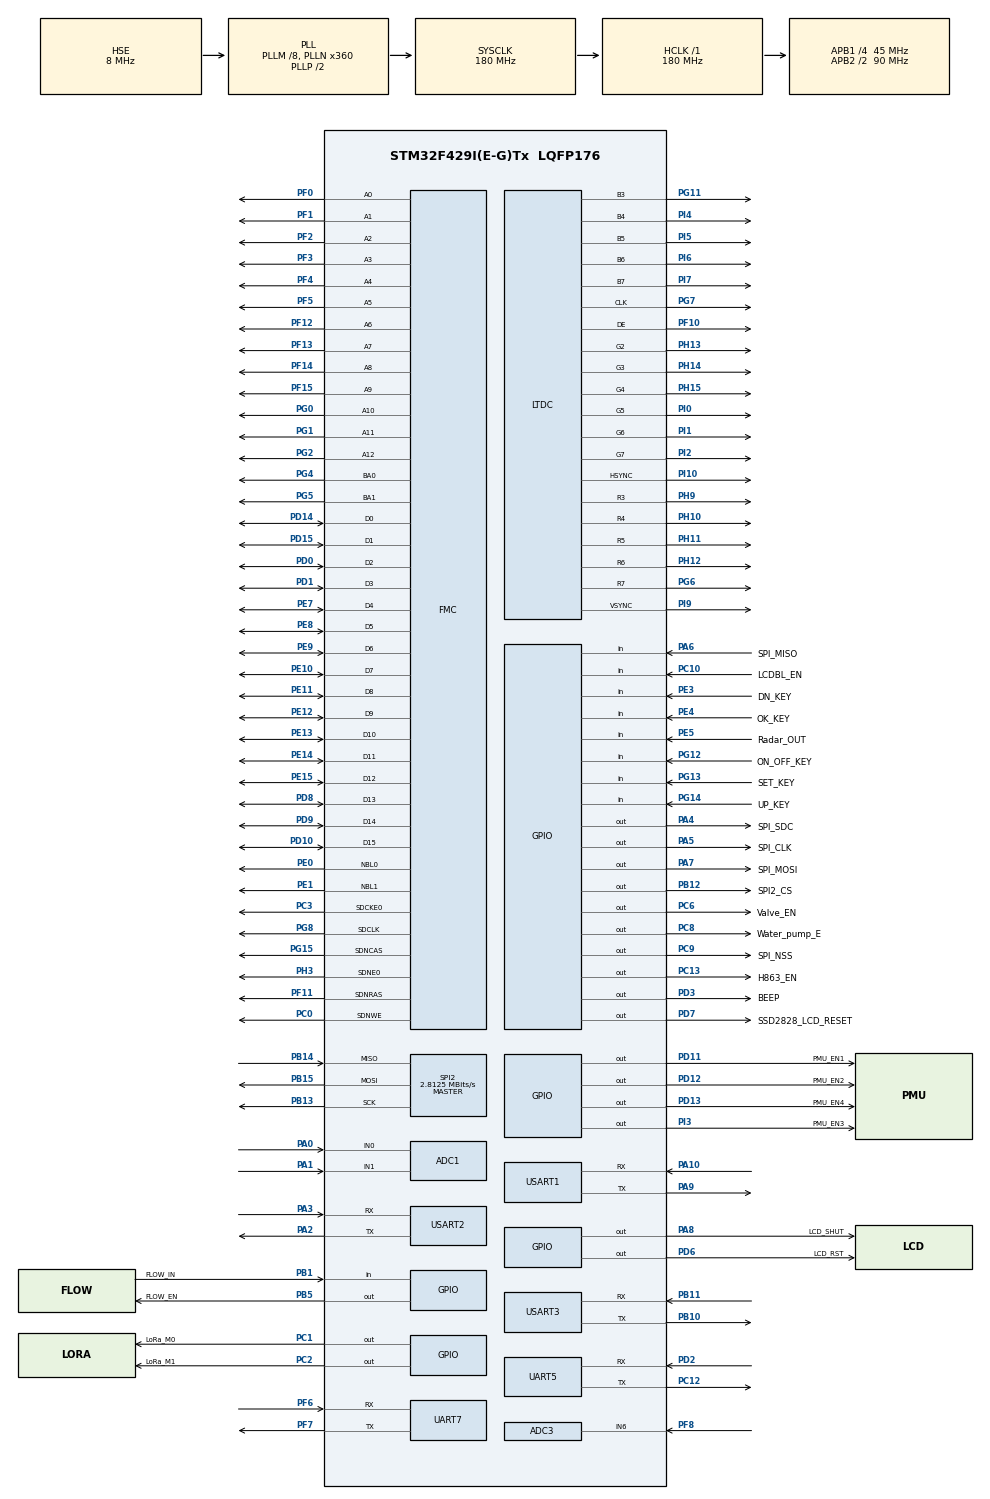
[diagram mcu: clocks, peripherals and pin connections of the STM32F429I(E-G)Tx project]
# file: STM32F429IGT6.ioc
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ADC1.Channel-1\#ChannelRegularConversion=ADC_CHANNEL_0
ADC1.Channel-2\#ChannelRegularConversion=ADC_CHANNEL_1
ADC1.ClockPrescaler=ADC_CLOCK_SYNC_PCLK_DIV4
ADC1.NbrOfConversion=2
ADC1.NbrOfConversionFlag=1
ADC1.Rank-1\#ChannelRegularConversion=1
ADC1.Rank-2\#ChannelRegularConversion=2
ADC1.SamplingTime-1\#ChannelRegularConversion=ADC_SAMPLETIME_144CYCLES
ADC1.SamplingTime-2\#ChannelRegularConversion=ADC_SAMPLETIME_144CYCLES
ADC1.ScanConvMode=ENABLE
ADC1.master=1
ADC3.Channel-0\#ChannelRegularConversion=ADC_CHANNEL_6
ADC3.ClockPrescaler=ADC_CLOCK_SYNC_PCLK_DIV4
ADC3.NbrOfConversionFlag=1
ADC3.Rank-0\#ChannelRegularConversion=1
ADC3.SamplingTime-0\#ChannelRegularConversion=ADC_SAMPLETIME_144CYCLES
FMC.CASLatency1=FMC_SDRAM_CAS_LATENCY_3
FMC.ColumnBitsNumber1=FMC_SDRAM_COLUMN_BITS_NUM_9
FMC.ExitSelfRefreshDelay1=8
FMC.LoadToActiveDelay1=2
FMC.RCDDelay1=3
FMC.RPDelay1=3
FMC.RPDelay2=3
FMC.ReadBurst1=FMC_SDRAM_RBURST_ENABLE
FMC.ReadBurst2=FMC_SDRAM_RBURST_ENABLE
FMC.ReadPipeDelay1=FMC_SDRAM_RPIPE_DELAY_1
FMC.ReadPipeDelay2=FMC_SDRAM_RPIPE_DELAY_1
FMC.RowCycleDelay1=8
FMC.RowCycleDelay2=8
FMC.SDClockPeriod1=FMC_SDRAM_CLOCK_PERIOD_2
FMC.SDClockPeriod2=FMC_SDRAM_CLOCK_PERIOD_2
FMC.SelfRefreshTime1=5
FMC.WriteRecoveryTime1=3
LTDC.ActiveH=960
LTDC.ActiveW=400
LTDC.Alpha_L0=255
LTDC.DEPolarity=LTDC_DEPOLARITY_AH
LTDC.FBStartAdress_L0=0xC0000000
LTDC.HBP=20
LTDC.HFP=20
LTDC.HSync=10
LTDC.ImageHeight_L0=960
LTDC.ImageWidth_L0=400
LTDC.Layers=0
LTDC.PixelFormat_L0=LTDC_PIXEL_FORMAT_RGB565
LTDC.VBP=24
LTDC.VFP=12
LTDC.VSync=8
LTDC.WindowX1_L0=400
LTDC.WindowY1_L0=960
Mcu.Family=STM32F4
Mcu.Name=STM32F429I(E-G)Tx
Mcu.Package=LQFP176
NVIC.PriorityGroup=NVIC_PRIORITYGROUP_4
PA0/WKUP.Signal=ADCx_IN0
PA1.Signal=ADCx_IN1
PA10.Mode=Asynchronous
PA10.Signal=USART1_RX
PA13.Mode=Serial_Wire
PA13.Signal=SYS_JTMS-SWDIO
PA14.Mode=Serial_Wire
PA14.Signal=SYS_JTCK-SWCLK
PA2.Mode=Asynchronous
PA2.Signal=USART2_TX
PA3.Mode=Asynchronous
PA3.Signal=USART2_RX
PA4.GPIO_Label=SPI_SDC
PA4.PinState=GPIO_PIN_SET
PA4.Signal=GPIO_Output
PA5.GPIO_Label=SPI_CLK
PA5.Signal=GPIO_Output
PA6.GPIO_Label=SPI_MISO
PA6.Signal=GPIO_Input
PA7.GPIO_Label=SPI_MOSI
PA7.Signal=GPIO_Output
PA8.GPIO_Label=LCD_SHUT
PA8.Signal=GPIO_Output
PA9.Mode=Asynchronous
PA9.Signal=USART1_TX
PB1.GPIO_Label=FLOW_IN
PB1.Signal=GPIO_Input
PB10.Mode=Asynchronous
PB10.Signal=USART3_TX
PB11.Mode=Asynchronous
PB11.Signal=USART3_RX
PB12.GPIO_Label=SPI2_CS
PB12.PinState=GPIO_PIN_SET
PB12.Signal=GPIO_Output
PB13.Mode=Full_Duplex_Master
PB13.Signal=SPI2_SCK
PB14.Mode=Full_Duplex_Master
PB14.Signal=SPI2_MISO
PB15.Mode=Full_Duplex_Master
PB15.Signal=SPI2_MOSI
PB5.GPIO_Label=FLOW_EN
PB5.PinState=GPIO_PIN_SET
PB5.Signal=GPIO_Output
PC0.Signal=FMC_SDNWE
PC1.GPIO_Label=LoRa_M0
PC1.Signal=GPIO_Output
PC10.GPIO_Label=LCDBL_EN
PC10.Signal=GPIO_Input
PC12.Mode=Asynchronous
PC12.Signal=UART5_TX
PC13.GPIO_Label=H863_EN
PC13.Signal=GPIO_Output
PC14/OSC32_IN.Mode=LSE-External-Oscillator
PC14/OSC32_IN.Signal=RCC_OSC32_IN
PC15/OSC32_OUT.Mode=LSE-External-Oscillator
PC15/OSC32_OUT.Signal=RCC_OSC32_OUT
PC2.GPIO_Label=LoRa_M1
PC2.Signal=GPIO_Output
PC3.Mode=SdramChipSelect1_1
PC3.Signal=FMC_SDCKE0
PC6.GPIO_Label=Valve_EN
PC6.Signal=GPIO_Output
PC8.GPIO_Label=Water_pump_E
PC8.Signal=GPIO_Output
PC9.GPIO_Label=SPI_NSS
PC9.PinState=GPIO_PIN_SET
PC9.Signal=GPIO_Output
PD0.Signal=FMC_D2_DA2
PD1.Signal=FMC_D3_DA3
PD10.Signal=FMC_D15_DA15
PD11.GPIO_Label=PMU_EN1
PD11.Signal=GPIO_Output
PD12.GPIO_Label=PMU_EN2
PD12.Signal=GPIO_Output
PD13.GPIO_Label=PMU_EN4
PD13.Signal=GPIO_Output
PD14.Signal=FMC_D0_DA0
PD15.Signal=FMC_D1_DA1
PD2.Mode=Asynchronous
PD2.Signal=UART5_RX
PD3.GPIO_Label=BEEP
PD3.Signal=GPIO_Output
PD6.GPIO_Label=LCD_RST
PD6.Signal=GPIO_Output
PD7.GPIO_Label=SSD2828_LCD_RESET
PD7.Signal=GPIO_Output
PD8.Signal=FMC_D13_DA13
PD9.Signal=FMC_D14_DA14
PE0.Signal=FMC_NBL0
PE1.Signal=FMC_NBL1
PE10.Signal=FMC_D7_DA7
PE11.Signal=FMC_D8_DA8
PE12.Signal=FMC_D9_DA9
PE13.Signal=FMC_D10_DA10
PE14.Signal=FMC_D11_DA11
PE15.Signal=FMC_D12_DA12
PE3.GPIO_Label=DN_KEY
PE3.GPIO_PuPd=GPIO_PULLUP
PE3.Signal=GPIO_Input
PE4.GPIO_Label=OK_KEY
PE4.GPIO_PuPd=GPIO_PULLUP
PE4.Signal=GPIO_Input
PE5.GPIO_Label=Radar_OUT
PE5.Signal=GPIO_Input
PE7.Signal=FMC_D4_DA4
PE8.Signal=FMC_D5_DA5
PE9.Signal=FMC_D6_DA6
PF0.Signal=FMC_A0
PF1.Signal=FMC_A1
PF10.GPIO_Speed=GPIO_SPEED_FREQ_VERY_HIGH
PF10.Mode=RGB565
PF10.Signal=LTDC_DE
PF11.Signal=FMC_SDNRAS
PF12.Signal=FMC_A6
PF13.Signal=FMC_A7
PF14.Signal=FMC_A8
PF15.Signal=FMC_A9
PF2.Signal=FMC_A2
PF3.Signal=FMC_A3
PF4.Signal=FMC_A4
PF5.Signal=FMC_A5
PF6.Mode=Asynchronous
PF6.Signal=UART7_RX
PF7.Mode=Asynchronous
PF7.Signal=UART7_TX
PF8.Mode=IN6
PF8.Signal=ADC3_IN6
PG0.Signal=FMC_A10
PG1.Signal=FMC_A11
PG11.GPIO_Speed=GPIO_SPEED_FREQ_VERY_HIGH
PG11.Mode=RGB565
PG11.Signal=LTDC_B3
PG12.GPIO_Label=ON_OFF_KEY
PG12.GPIO_PuPd=GPIO_PULLUP
PG12.Signal=GPIO_Input
PG13.GPIO_Label=SET_KEY
PG13.GPIO_PuPd=GPIO_PULLUP
PG13.Signal=GPIO_Input
PG14.GPIO_Label=UP_KEY
PG14.GPIO_PuPd=GPIO_PULLUP
PG14.Signal=GPIO_Input
PG15.Signal=FMC_SDNCAS
PG2.Signal=FMC_A12
PG4.Signal=FMC_A14_BA0
PG5.Signal=FMC_A15_BA1
PG6.GPIO_Speed=GPIO_SPEED_FREQ_VERY_HIGH
PG6.Mode=RGB565
PG6.Signal=LTDC_R7
PG7.GPIO_Speed=GPIO_SPEED_FREQ_VERY_HIGH
PG7.Mode=RGB565
PG7.Signal=LTDC_CLK
PG8.Signal=FMC_SDCLK
PH0/OSC_IN.Mode=HSE-External-Oscillator
PH0/OSC_IN.Signal=RCC_OSC_IN
PH1/OSC_OUT.Mode=HSE-External-Oscillator
PH1/OSC_OUT.Signal=RCC_OSC_OUT
PH10.GPIO_Speed=GPIO_SPEED_FREQ_VERY_HIGH
PH10.Mode=RGB565
PH10.Signal=LTDC_R4
PH11.GPIO_Speed=GPIO_SPEED_FREQ_VERY_HIGH
PH11.Mode=RGB565
PH11.Signal=LTDC_R5
PH12.GPIO_Speed=GPIO_SPEED_FREQ_VERY_HIGH
PH12.Mode=RGB565
PH12.Signal=LTDC_R6
PH13.GPIO_Speed=GPIO_SPEED_FREQ_VERY_HIGH
PH13.Mode=RGB565
PH13.Signal=LTDC_G2
PH14.GPIO_Speed=GPIO_SPEED_FREQ_VERY_HIGH
PH14.Mode=RGB565
PH14.Signal=LTDC_G3
PH15.GPIO_Speed=GPIO_SPEED_FREQ_VERY_HIGH
PH15.Mode=RGB565
PH15.Signal=LTDC_G4
PH3.Mode=SdramChipSelect1_1
PH3.Signal=FMC_SDNE0
PH9.GPIO_Speed=GPIO_SPEED_FREQ_VERY_HIGH
PH9.Mode=RGB565
PH9.Signal=LTDC_R3
PI0.GPIO_Speed=GPIO_SPEED_FREQ_VERY_HIGH
PI0.Mode=RGB565
PI0.Signal=LTDC_G5
PI1.GPIO_Speed=GPIO_SPEED_FREQ_VERY_HIGH
PI1.Mode=RGB565
PI1.Signal=LTDC_G6
PI10.GPIO_Speed=GPIO_SPEED_FREQ_VERY_HIGH
PI10.Mode=RGB565
PI10.Signal=LTDC_HSYNC
PI2.GPIO_Speed=GPIO_SPEED_FREQ_VERY_HIGH
PI2.Mode=RGB565
PI2.Signal=LTDC_G7
PI3.GPIO_Label=PMU_EN3
PI3.Signal=GPIO_Output
PI4.GPIO_Speed=GPIO_SPEED_FREQ_VERY_HIGH
PI4.Mode=RGB565
PI4.Signal=LTDC_B4
PI5.GPIO_Speed=GPIO_SPEED_FREQ_VERY_HIGH
PI5.Mode=RGB565
PI5.Signal=LTDC_B5
PI6.GPIO_Speed=GPIO_SPEED_FREQ_VERY_HIGH
PI6.Mode=RGB565
PI6.Signal=LTDC_B6
PI7.GPIO_Speed=GPIO_SPEED_FREQ_VERY_HIGH
PI7.Mode=RGB565
PI7.Signal=LTDC_B7
PI9.GPIO_Speed=GPIO_SPEED_FREQ_VERY_HIGH
PI9.Mode=RGB565
PI9.Signal=LTDC_VSYNC
ProjectManager.HeapSize=0x200
ProjectManager.StackSize=0x400
ProjectManager.TargetToolchain=CMake
RCC.48MHZClocksFreq_Value=90000000
RCC.AHBFreq_Value=180000000
RCC.APB1CLKDivider=RCC_HCLK_DIV4
RCC.APB1Freq_Value=45000000
RCC.APB1TimFreq_Value=90000000
RCC.APB2CLKDivider=RCC_HCLK_DIV2
RCC.APB2Freq_Value=90000000
RCC.APB2TimFreq_Value=180000000
RCC.CortexFreq_Value=180000000
RCC.HCLKFreq_Value=180000000
RCC.HSE_VALUE=8000000
RCC.HSI_VALUE=16000000
RCC.PLLM=8
RCC.PLLN=360
RCC.PLLSAIN=271
RCC.PLLSAIR=5
RCC.PLLSourceVirtual=RCC_PLLSOURCE_HSE
RCC.RCC_RTC_Clock_Source=RCC_RTCCLKSOURCE_LSI
RCC.RCC_RTC_Clock_SourceVirtual=RCC_RTCCLKSOURCE_LSI
RCC.SYSCLKFreq_VALUE=180000000
RCC.SYSCLKSource=RCC_SYSCLKSOURCE_PLLCLK
RCC.VCOOutputFreq_Value=360000000
SH.ADCx_IN0.0=ADC1_IN0,IN0
SH.ADCx_IN1.0=ADC1_IN1,IN1
SH.FMC_A0.0=FMC_A0,13b-sda1
SH.FMC_A1.0=FMC_A1,13b-sda1
SH.FMC_A10.0=FMC_A10,13b-sda1
SH.FMC_A11.0=FMC_A11,13b-sda1
SH.FMC_A12.0=FMC_A12,13b-sda1
SH.FMC_A14_BA0.0=FMC_BA0,FourSdramBanks1
SH.FMC_A15_BA1.0=FMC_BA1,FourSdramBanks1
SH.FMC_A2.0=FMC_A2,13b-sda1
SH.FMC_A3.0=FMC_A3,13b-sda1
SH.FMC_A4.0=FMC_A4,13b-sda1
SH.FMC_A5.0=FMC_A5,13b-sda1
SH.FMC_A6.0=FMC_A6,13b-sda1
SH.FMC_A7.0=FMC_A7,13b-sda1
SH.FMC_A8.0=FMC_A8,13b-sda1
SH.FMC_A9.0=FMC_A9,13b-sda1
SH.FMC_D0_DA0.0=FMC_D0,sd-16b-d1
SH.FMC_D10_DA10.0=FMC_D10,sd-16b-d1
SH.FMC_D11_DA11.0=FMC_D11,sd-16b-d1
SH.FMC_D12_DA12.0=FMC_D12,sd-16b-d1
SH.FMC_D13_DA13.0=FMC_D13,sd-16b-d1
SH.FMC_D14_DA14.0=FMC_D14,sd-16b-d1
SH.FMC_D15_DA15.0=FMC_D15,sd-16b-d1
SH.FMC_D1_DA1.0=FMC_D1,sd-16b-d1
SH.FMC_D2_DA2.0=FMC_D2,sd-16b-d1
SH.FMC_D3_DA3.0=FMC_D3,sd-16b-d1
SH.FMC_D4_DA4.0=FMC_D4,sd-16b-d1
SH.FMC_D5_DA5.0=FMC_D5,sd-16b-d1
SH.FMC_D6_DA6.0=FMC_D6,sd-16b-d1
SH.FMC_D7_DA7.0=FMC_D7,sd-16b-d1
SH.FMC_D8_DA8.0=FMC_D8,sd-16b-d1
SH.FMC_D9_DA9.0=FMC_D9,sd-16b-d1
SH.FMC_NBL0.0=FMC_NBL0,Sd2ByteEnable1
SH.FMC_NBL1.0=FMC_NBL1,Sd2ByteEnable1
SH.FMC_SDCLK.0=FMC_SDCLK,13b-sda1
SH.FMC_SDNCAS.0=FMC_SDNCAS,13b-sda1
SH.FMC_SDNRAS.0=FMC_SDNRAS,13b-sda1
SH.FMC_SDNWE.0=FMC_SDNWE,13b-sda1
SPI2.BaudRatePrescaler=SPI_BAUDRATEPRESCALER_16
SPI2.CalculateBaudRate=2.8125 MBits/s
SPI2.Direction=SPI_DIRECTION_2LINES
SPI2.Mode=SPI_MODE_MASTER
SPI2.VirtualType=VM_MASTER
UART5.VirtualMode=Asynchronous
UART7.VirtualMode=Asynchronous
USART1.VirtualMode=VM_ASYNC
USART2.VirtualMode=VM_ASYNC
USART3.VirtualMode=VM_ASYNC
board=custom

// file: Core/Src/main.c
/* USER CODE BEGIN Header */
/**
  ******************************************************************************
  * @file           : main.c
  * @brief          : Main program body
  ******************************************************************************
  * @attention
  *
  * Copyright (c) 2026 STMicroelectronics.
  * All rights reserved.
  *
  * This software is licensed under terms that can be found in the LICENSE file
  * in the root directory of this software component.
  * If no LICENSE file comes with this software, it is provided AS-IS.
  *
  ******************************************************************************
  */
/* USER CODE END Header */
#include "main.h"

/* USER CODE BEGIN Includes */
#include "board_sdram.h"
#include "debug_log.h"
#include "firmware_version.h"
#include "display_config.h"
#include "board_ssd2828.h"
#include "board_display_diag.h"
#include "board_test.h"
  /* USER CODE END Includes */

/* USER CODE BEGIN PD */
#define SCREEN_FRAME0 ((volatile uint16_t *)BOARD_SDRAM_BASE_ADDRESS)
#define SCREEN_FRAME1 ((volatile uint16_t *)(BOARD_SDRAM_BASE_ADDRESS + DISPLAY_TEST_FRAME_BYTES))
_Static_assert(2u * DISPLAY_TEST_FRAME_BYTES <= BOARD_SDRAM_SIZE_BYTES, "Two test frames must fit SDRAM");
  /* USER CODE END PD */

ADC_HandleTypeDef hadc1;
ADC_HandleTypeDef hadc3;

LTDC_HandleTypeDef hltdc;

SPI_HandleTypeDef hspi2;

UART_HandleTypeDef huart5;
UART_HandleTypeDef huart7;
UART_HandleTypeDef huart1;
UART_HandleTypeDef huart2;
UART_HandleTypeDef huart3;

SDRAM_HandleTypeDef hsdram1;

/* USER CODE BEGIN PV */
static BoardSDRAM_Report sdram_report;
static SSD2828_ProbeReport bridge_report;
static SSD2828_Status bridge_status = SSD2828_INVALID_ARGUMENT;
static BoardSSD2828_DisplayReport panel_report;
static SSD2828_Status panel_status = SSD2828_INVALID_ARGUMENT;
static BoardDisplayDiag display_diag;
static BoardTest board_test;
static bool ltdc_scan_active, screen_active;
  /* USER CODE END PV */

void SystemClock_Config(void);
static void MX_GPIO_Init(void);
static void MX_UART5_Init(void);
static void MX_FMC_Init(void);
static void MX_ADC1_Init(void);
static void MX_LTDC_Init(void);
static void MX_UART7_Init(void);
static void MX_USART1_UART_Init(void);
static void MX_USART3_UART_Init(void);
static void MX_ADC3_Init(void);
static void MX_SPI2_Init(void);
static void MX_USART2_UART_Init(void);

/* USER CODE BEGIN 0 */

/* RM0090 calls the output "Not Data Enable". DEPOL=0 is the physical
   active-HIGH DE used by Linux/U-Boot STM32 LTDC and required by SSD2828.
   Observe the MCU pad in wide interior regions, not CDSR internal status.
   Run ONLY before the bridge video path is enabled. This is logic-level
   evidence at PF10, not a measurement at the bridge or of setup/hold time. */
static unsigned DisplayDE_Region(uint32_t position)
{
  uint32_t x = (position & LTDC_CPSR_CXPOS) >> LTDC_CPSR_CXPOS_Pos;
  uint32_t y = (position & LTDC_CPSR_CYPOS) >> LTDC_CPSR_CYPOS_Pos;
  /* Current scan: HBP=30, VBP=32, active=400x960, totals=450x1004. */
  if (x < 64u || x > 395u) return 0u;
  if (y >= 64u && y <= 959u) return 1u;
  if (y >= 10u && y <= 23u) return 2u; /* Wide vertical back porch. */
  return 0u;
}

static void DisplayDE_LogPad(const char *phase)
{
  uint32_t counts[2][2] = {{0u, 0u}, {0u, 0u}};
  uint32_t start = HAL_GetTick();
  uint32_t polls = 0u;
  /* Both bounds apply: broken scan/tick must not block panel startup. */
  while ((uint32_t)(HAL_GetTick() - start) < 120u && polls < 2000000u)
  {
    ++polls;
    uint32_t before = LTDC->CPSR;
    uint32_t pad = (GPIOF->IDR & GPIO_PIN_10) != 0u;
    uint32_t after = LTDC->CPSR;
    unsigned region = DisplayDE_Region(before);
    uint32_t xb = before >> LTDC_CPSR_CXPOS_Pos;
    uint32_t xa = after >> LTDC_CPSR_CXPOS_Pos;
    /* Reject scan boundaries, wrap and samples delayed by interrupts. */
    if (region != 0u && region == DisplayDE_Region(after) &&
        (before & LTDC_CPSR_CYPOS) == (after & LTDC_CPSR_CYPOS) &&
        xa >= xb && xa - xb <= 32u)
      ++counts[region - 1u][pad];
  }
  uint32_t mode = (GPIOF->MODER >> 20u) & 3u;
  uint32_t af = (GPIOF->AFR[1] >> 8u) & 15u;
  const char *physical = "INSUFFICIENT";
  if (mode != 2u || af != 14u) physical = "PIN-CONFIG";
  else if (counts[0][0] + counts[0][1] >= 32u &&
           counts[1][0] + counts[1][1] >= 32u)
  {
    if (counts[0][0] == 0u && counts[1][1] == 0u) physical = "ACTIVE-HIGH";
    else if (counts[0][1] == 0u && counts[1][0] == 0u) physical = "ACTIVE-LOW";
    else physical = "MIXED";
  }
  (void)DebugLog_Printf("[DE-PAD] phase=%s GCR=%08lX cache=%08lX PF10mode=%lu AF=%lu active(H/L)=%lu/%lu blank(H/L)=%lu/%lu physical=%s polls=%lu\r\n",
                       phase, (unsigned long)LTDC->GCR,
                       (unsigned long)hltdc.Init.DEPolarity,
                       (unsigned long)mode, (unsigned long)af,
                       (unsigned long)counts[0][1], (unsigned long)counts[0][0],
                       (unsigned long)counts[1][1], (unsigned long)counts[1][0],
                       physical, (unsigned long)polls);
}

/* USER CODE END 0 */

int main(void)
{

  /* MCU Configuration--------------------------------------------------------*/

  /* Reset of all peripherals, Initializes the Flash interface and the Systick. */
  HAL_Init();

  /* Configure the system clock */
  SystemClock_Config();

  /* Initialize all configured peripherals */
  MX_GPIO_Init();
  MX_UART5_Init();
  MX_FMC_Init();
  MX_ADC1_Init();
  MX_UART7_Init();
  MX_USART1_UART_Init();
  MX_USART3_UART_Init();
  MX_ADC3_Init();
  MX_SPI2_Init();
  MX_USART2_UART_Init();
  /* USER CODE BEGIN 2 */
  BoardTest_Init(&board_test, HAL_GetTick());
  bridge_status = BoardSSD2828_Probe(&bridge_report);
  if (bridge_status == SSD2828_OK)
  {
    DebugLog_SetStage("ltdc-start");
    MX_LTDC_Init();
    ltdc_scan_active = true;
    (void)DebugLog_Write("[LTDC] scan=ON PCLK=27100000Hz totals=450x1004 RGB565\r\n");
    if (BoardDisplayDiag_Prepare(&display_diag, &hltdc, SCREEN_FRAME0, DISPLAY_TEST_FRAME_BYTES))
    {
      bridge_status = BoardSSD2828_CollectPanelEvidence(&bridge_report);
      panel_status = bridge_status;
      if (bridge_status == SSD2828_OK)
        panel_status = BoardSSD2828_StartPanel(true, &panel_report);
      BoardTest_SetStartup(&board_test, true, bridge_status == SSD2828_OK,
                           bridge_report.id_count != 0u ? bridge_report.id[0] : 0u,
                           panel_status == SSD2828_OK);
      if (panel_status == SSD2828_OK)
        screen_active = BoardTest_AttachDisplay(&board_test, &hltdc,
                                                SCREEN_FRAME0, SCREEN_FRAME1, DISPLAY_TEST_FRAME_BYTES);
    }
    if (!screen_active)
    {
      BoardSSD2828_Shutdown();
      __HAL_LTDC_DISABLE(&hltdc);
      ltdc_scan_active = false;
    }
  }
  else
  {
    (void)DebugLog_Printf("[LTDC] scan=OFF bridge-status=%u phase=%s\r\n",
                         (unsigned)bridge_status, bridge_report.phase);
  }
  BoardTest_SetStartup(&board_test, true, bridge_status == SSD2828_OK,
                       bridge_report.id_count != 0u ? bridge_report.id[0] : 0u,
                       panel_status == SSD2828_OK);
  DebugLog_SetStage(screen_active ? "board-key-buzzer-test" : "display-failed-key-test");
  /* USER CODE END 2 */

  /* Infinite loop */
  while (1)
  {

    /* USER CODE BEGIN 3 */
    HAL_Delay(5u);
    BoardTest_Update(&board_test, HAL_GetTick());
    if (screen_active && !board_test.attached)
    {
      BoardSSD2828_Shutdown();
      screen_active = ltdc_scan_active = false;
    }
  }
  /* USER CODE END 3 */
}

void SystemClock_Config(void)
{
  RCC_OscInitTypeDef RCC_OscInitStruct = {0};
  RCC_ClkInitTypeDef RCC_ClkInitStruct = {0};

  /** Configure the main internal regulator output voltage
  */
  __HAL_RCC_PWR_CLK_ENABLE();
  __HAL_PWR_VOLTAGESCALING_CONFIG(PWR_REGULATOR_VOLTAGE_SCALE1);

  /** Initializes the RCC Oscillators according to the specified parameters
  * in the RCC_OscInitTypeDef structure.
  */
  RCC_OscInitStruct.OscillatorType = RCC_OSCILLATORTYPE_HSE;
  RCC_OscInitStruct.HSEState = RCC_HSE_ON;
  RCC_OscInitStruct.PLL.PLLState = RCC_PLL_ON;
  RCC_OscInitStruct.PLL.PLLSource = RCC_PLLSOURCE_HSE;
  RCC_OscInitStruct.PLL.PLLM = 8;
  RCC_OscInitStruct.PLL.PLLN = 360;
  RCC_OscInitStruct.PLL.PLLP = RCC_PLLP_DIV2;
  RCC_OscInitStruct.PLL.PLLQ = 4;
  if (HAL_RCC_OscConfig(&RCC_OscInitStruct) != HAL_OK)
  {
    Error_Handler();
  }

  /** Activate the Over-Drive mode
  */
  if (HAL_PWREx_EnableOverDrive() != HAL_OK)
  {
    Error_Handler();
  }

  /** Initializes the CPU, AHB and APB buses clocks
  */
  RCC_ClkInitStruct.ClockType = RCC_CLOCKTYPE_HCLK|RCC_CLOCKTYPE_SYSCLK
                              |RCC_CLOCKTYPE_PCLK1|RCC_CLOCKTYPE_PCLK2;
  RCC_ClkInitStruct.SYSCLKSource = RCC_SYSCLKSOURCE_PLLCLK;
  RCC_ClkInitStruct.AHBCLKDivider = RCC_SYSCLK_DIV1;
  RCC_ClkInitStruct.APB1CLKDivider = RCC_HCLK_DIV4;
  RCC_ClkInitStruct.APB2CLKDivider = RCC_HCLK_DIV2;

  if (HAL_RCC_ClockConfig(&RCC_ClkInitStruct, FLASH_LATENCY_5) != HAL_OK)
  {
    Error_Handler();
  }
}

static void MX_ADC1_Init(void)
{

  ADC_ChannelConfTypeDef sConfig = {0};

  /** Configure the global features of the ADC (Clock, Resolution, Data Alignment and number of conversion)
  */
  hadc1.Instance = ADC1;
  hadc1.Init.ClockPrescaler = ADC_CLOCK_SYNC_PCLK_DIV4;
  hadc1.Init.Resolution = ADC_RESOLUTION_12B;
  hadc1.Init.ScanConvMode = ENABLE;
  hadc1.Init.ContinuousConvMode = DISABLE;
  hadc1.Init.DiscontinuousConvMode = DISABLE;
  hadc1.Init.ExternalTrigConvEdge = ADC_EXTERNALTRIGCONVEDGE_NONE;
  hadc1.Init.ExternalTrigConv = ADC_SOFTWARE_START;
  hadc1.Init.DataAlign = ADC_DATAALIGN_RIGHT;
  hadc1.Init.NbrOfConversion = 2;
  hadc1.Init.DMAContinuousRequests = DISABLE;
  hadc1.Init.EOCSelection = ADC_EOC_SINGLE_CONV;
  if (HAL_ADC_Init(&hadc1) != HAL_OK)
  {
    Error_Handler();
  }

  /** Configure for the selected ADC regular channel its corresponding rank in the sequencer and its sample time.
  */
  sConfig.Channel = ADC_CHANNEL_0;
  sConfig.Rank = 1;
  sConfig.SamplingTime = ADC_SAMPLETIME_144CYCLES;
  if (HAL_ADC_ConfigChannel(&hadc1, &sConfig) != HAL_OK)
  {
    Error_Handler();
  }

  /** Configure for the selected ADC regular channel its corresponding rank in the sequencer and its sample time.
  */
  sConfig.Channel = ADC_CHANNEL_1;
  sConfig.Rank = 2;
  if (HAL_ADC_ConfigChannel(&hadc1, &sConfig) != HAL_OK)
  {
    Error_Handler();
  }

}

static void MX_ADC3_Init(void)
{

  ADC_ChannelConfTypeDef sConfig = {0};

  /** Configure the global features of the ADC (Clock, Resolution, Data Alignment and number of conversion)
  */
  hadc3.Instance = ADC3;
  hadc3.Init.ClockPrescaler = ADC_CLOCK_SYNC_PCLK_DIV4;
  hadc3.Init.Resolution = ADC_RESOLUTION_12B;
  hadc3.Init.ScanConvMode = DISABLE;
  hadc3.Init.ContinuousConvMode = DISABLE;
  hadc3.Init.DiscontinuousConvMode = DISABLE;
  hadc3.Init.ExternalTrigConvEdge = ADC_EXTERNALTRIGCONVEDGE_NONE;
  hadc3.Init.ExternalTrigConv = ADC_SOFTWARE_START;
  hadc3.Init.DataAlign = ADC_DATAALIGN_RIGHT;
  hadc3.Init.NbrOfConversion = 1;
  hadc3.Init.DMAContinuousRequests = DISABLE;
  hadc3.Init.EOCSelection = ADC_EOC_SINGLE_CONV;
  if (HAL_ADC_Init(&hadc3) != HAL_OK)
  {
    Error_Handler();
  }

  /** Configure for the selected ADC regular channel its corresponding rank in the sequencer and its sample time.
  */
  sConfig.Channel = ADC_CHANNEL_6;
  sConfig.Rank = 1;
  sConfig.SamplingTime = ADC_SAMPLETIME_144CYCLES;
  if (HAL_ADC_ConfigChannel(&hadc3, &sConfig) != HAL_OK)
  {
    Error_Handler();
  }

}

static void MX_LTDC_Init(void)
{

  LTDC_LayerCfgTypeDef pLayerCfg = {0};

  hltdc.Instance = LTDC;
  hltdc.Init.HSPolarity = LTDC_HSPOLARITY_AL;
  hltdc.Init.VSPolarity = LTDC_VSPOLARITY_AL;
  hltdc.Init.DEPolarity = LTDC_DEPOLARITY_AH;
  hltdc.Init.PCPolarity = LTDC_PCPOLARITY_IPC;
  hltdc.Init.HorizontalSync = 9;
  hltdc.Init.VerticalSync = 7;
  hltdc.Init.AccumulatedHBP = 29;
  hltdc.Init.AccumulatedVBP = 31;
  hltdc.Init.AccumulatedActiveW = 429;
  hltdc.Init.AccumulatedActiveH = 991;
  hltdc.Init.TotalWidth = 449;
  hltdc.Init.TotalHeigh = 1003;
  hltdc.Init.Backcolor.Blue = 0;
  hltdc.Init.Backcolor.Green = 0;
  hltdc.Init.Backcolor.Red = 0;
  if (HAL_LTDC_Init(&hltdc) != HAL_OK)
  {
    Error_Handler();
  }
  pLayerCfg.WindowX0 = 0;
  pLayerCfg.WindowX1 = 400;
  pLayerCfg.WindowY0 = 0;
  pLayerCfg.WindowY1 = 960;
  pLayerCfg.PixelFormat = LTDC_PIXEL_FORMAT_RGB565;
  pLayerCfg.Alpha = 255;
  pLayerCfg.Alpha0 = 0;
  pLayerCfg.BlendingFactor1 = LTDC_BLENDING_FACTOR1_CA;
  pLayerCfg.BlendingFactor2 = LTDC_BLENDING_FACTOR2_CA;
  pLayerCfg.FBStartAdress = 0xC0000000;
  pLayerCfg.ImageWidth = 400;
  pLayerCfg.ImageHeight = 960;
  pLayerCfg.Backcolor.Blue = 0;
  pLayerCfg.Backcolor.Green = 0;
  pLayerCfg.Backcolor.Red = 0;
  if (HAL_LTDC_ConfigLayer(&hltdc, &pLayerCfg, 0) != HAL_OK)
  {
    Error_Handler();
  }
  /* USER CODE BEGIN LTDC_Init 2 */
  /* Keep generated/IOC content intact until the user selects DE Active Low
     in CubeMX. Sync both the HAL cache and the actual non-shadow GCR bit.
     Bridge VEN is still 0 here, so changing DE cannot interrupt video. */
  DisplayDE_LogPad("generated");
  hltdc.Init.DEPolarity = LTDC_DEPOLARITY_AL;
  CLEAR_BIT(hltdc.Instance->GCR, LTDC_GCR_DEPOL);
  __DSB();
  DisplayDE_LogPad("ssd2828");
  /* USER CODE END LTDC_Init 2 */

}

static void MX_SPI2_Init(void)
{

  /* SPI2 parameter configuration*/
  hspi2.Instance = SPI2;
  hspi2.Init.Mode = SPI_MODE_MASTER;
  hspi2.Init.Direction = SPI_DIRECTION_2LINES;
  hspi2.Init.DataSize = SPI_DATASIZE_8BIT;
  hspi2.Init.CLKPolarity = SPI_POLARITY_LOW;
  hspi2.Init.CLKPhase = SPI_PHASE_1EDGE;
  hspi2.Init.NSS = SPI_NSS_SOFT;
  hspi2.Init.BaudRatePrescaler = SPI_BAUDRATEPRESCALER_16;
  hspi2.Init.FirstBit = SPI_FIRSTBIT_MSB;
  hspi2.Init.TIMode = SPI_TIMODE_DISABLE;
  hspi2.Init.CRCCalculation = SPI_CRCCALCULATION_DISABLE;
  hspi2.Init.CRCPolynomial = 10;
  if (HAL_SPI_Init(&hspi2) != HAL_OK)
  {
    Error_Handler();
  }

}

static void MX_UART5_Init(void)
{

  huart5.Instance = UART5;
  huart5.Init.BaudRate = 115200;
  huart5.Init.WordLength = UART_WORDLENGTH_8B;
  huart5.Init.StopBits = UART_STOPBITS_1;
  huart5.Init.Parity = UART_PARITY_NONE;
  huart5.Init.Mode = UART_MODE_TX_RX;
  huart5.Init.HwFlowCtl = UART_HWCONTROL_NONE;
  huart5.Init.OverSampling = UART_OVERSAMPLING_16;
  if (HAL_UART_Init(&huart5) != HAL_OK)
  {
    Error_Handler();
  }
  /* USER CODE BEGIN UART5_Init 2 */
  DebugLog_Init(&huart5);
  DebugLog_SetStage("uart5-ready");
  (void)DebugLog_Write("\r\n[BOOT] H863 " H863_FIRMWARE_VERSION ": CW90 960x400 KEY/BEEP test; DE active-HIGH (DEPOL=0) + pad check; PD6 open-drain; boot panel-read + bridge/panel restart; FIXED " H863_DISPLAY_FIXED_LABEL "; GC9503 BOE3.99\r\n");
  (void)DebugLog_Printf("[CLOCK] SYSCLK=%lu HCLK=%lu PCLK1=%lu PCLK2=%lu Hz\r\n",
                       (unsigned long)HAL_RCC_GetSysClockFreq(),
                       (unsigned long)HAL_RCC_GetHCLKFreq(),
                       (unsigned long)HAL_RCC_GetPCLK1Freq(),
                       (unsigned long)HAL_RCC_GetPCLK2Freq());
  /* Register configuration only: a 1V8 reset high is not a 3V3 GPIO IDR test. */
  (void)DebugLog_Printf("[RESET] PD6 mode=%lu type=%lu pull=%lu latch=%lu; external 1V8 pull-up required (GPIO config, not volts)\r\n",
                       (unsigned long)((LCD_RST_GPIO_Port->MODER >> 12u) & 3u),
                       (unsigned long)((LCD_RST_GPIO_Port->OTYPER >> 6u) & 1u),
                       (unsigned long)((LCD_RST_GPIO_Port->PUPDR >> 12u) & 3u),
                       (unsigned long)((LCD_RST_GPIO_Port->ODR >> 6u) & 1u));
  /* USER CODE END UART5_Init 2 */

}

static void MX_UART7_Init(void)
{

  huart7.Instance = UART7;
  huart7.Init.BaudRate = 115200;
  huart7.Init.WordLength = UART_WORDLENGTH_8B;
  huart7.Init.StopBits = UART_STOPBITS_1;
  huart7.Init.Parity = UART_PARITY_NONE;
  huart7.Init.Mode = UART_MODE_TX_RX;
  huart7.Init.HwFlowCtl = UART_HWCONTROL_NONE;
  huart7.Init.OverSampling = UART_OVERSAMPLING_16;
  if (HAL_UART_Init(&huart7) != HAL_OK)
  {
    Error_Handler();
  }

}

static void MX_USART1_UART_Init(void)
{

  huart1.Instance = USART1;
  huart1.Init.BaudRate = 115200;
  huart1.Init.WordLength = UART_WORDLENGTH_8B;
  huart1.Init.StopBits = UART_STOPBITS_1;
  huart1.Init.Parity = UART_PARITY_NONE;
  huart1.Init.Mode = UART_MODE_TX_RX;
  huart1.Init.HwFlowCtl = UART_HWCONTROL_NONE;
  huart1.Init.OverSampling = UART_OVERSAMPLING_16;
  if (HAL_UART_Init(&huart1) != HAL_OK)
  {
    Error_Handler();
  }

}

static void MX_USART2_UART_Init(void)
{

  huart2.Instance = USART2;
  huart2.Init.BaudRate = 115200;
  huart2.Init.WordLength = UART_WORDLENGTH_8B;
  huart2.Init.StopBits = UART_STOPBITS_1;
  huart2.Init.Parity = UART_PARITY_NONE;
  huart2.Init.Mode = UART_MODE_TX_RX;
  huart2.Init.HwFlowCtl = UART_HWCONTROL_NONE;
  huart2.Init.OverSampling = UART_OVERSAMPLING_16;
  if (HAL_UART_Init(&huart2) != HAL_OK)
  {
    Error_Handler();
  }

}

static void MX_USART3_UART_Init(void)
{

  huart3.Instance = USART3;
  huart3.Init.BaudRate = 115200;
  huart3.Init.WordLength = UART_WORDLENGTH_8B;
  huart3.Init.StopBits = UART_STOPBITS_1;
  huart3.Init.Parity = UART_PARITY_NONE;
  huart3.Init.Mode = UART_MODE_TX_RX;
  huart3.Init.HwFlowCtl = UART_HWCONTROL_NONE;
  huart3.Init.OverSampling = UART_OVERSAMPLING_16;
  if (HAL_UART_Init(&huart3) != HAL_OK)
  {
    Error_Handler();
  }

}

/* FMC initialization function */
static void MX_FMC_Init(void)
{

  /* USER CODE BEGIN FMC_Init 0 */
  DebugLog_SetStage("fmc-controller-init");
  (void)DebugLog_Write("[FMC] controller-init\r\n");
  /* USER CODE END FMC_Init 0 */

  FMC_SDRAM_TimingTypeDef SdramTiming = {0};

  /** Perform the SDRAM1 memory initialization sequence
  */
  hsdram1.Instance = FMC_SDRAM_DEVICE;
  /* hsdram1.Init */
  hsdram1.Init.SDBank = FMC_SDRAM_BANK1;
  hsdram1.Init.ColumnBitsNumber = FMC_SDRAM_COLUMN_BITS_NUM_9;
  hsdram1.Init.RowBitsNumber = FMC_SDRAM_ROW_BITS_NUM_13;
  hsdram1.Init.MemoryDataWidth = FMC_SDRAM_MEM_BUS_WIDTH_16;
  hsdram1.Init.InternalBankNumber = FMC_SDRAM_INTERN_BANKS_NUM_4;
  hsdram1.Init.CASLatency = FMC_SDRAM_CAS_LATENCY_3;
  hsdram1.Init.WriteProtection = FMC_SDRAM_WRITE_PROTECTION_DISABLE;
  hsdram1.Init.SDClockPeriod = FMC_SDRAM_CLOCK_PERIOD_2;
  hsdram1.Init.ReadBurst = FMC_SDRAM_RBURST_ENABLE;
  hsdram1.Init.ReadPipeDelay = FMC_SDRAM_RPIPE_DELAY_1;
  /* SdramTiming */
  SdramTiming.LoadToActiveDelay = 2;
  SdramTiming.ExitSelfRefreshDelay = 8;
  SdramTiming.SelfRefreshTime = 5;
  SdramTiming.RowCycleDelay = 8;
  SdramTiming.WriteRecoveryTime = 3;
  SdramTiming.RPDelay = 3;
  SdramTiming.RCDDelay = 3;

  if (HAL_SDRAM_Init(&hsdram1, &SdramTiming) != HAL_OK)
  {
    Error_Handler( );
  }

  /* USER CODE BEGIN FMC_Init 2 */
  (void)DebugLog_Printf("[MCU] IDCODE=0x%08lX\r\n", (unsigned long)DBGMCU->IDCODE);
  (void)DebugLog_Printf("[FMC][REG] SDCR1=0x%08lX SDTR1=0x%08lX\r\n",
                       (unsigned long)hsdram1.Instance->SDCR[0],
                       (unsigned long)hsdram1.Instance->SDTR[0]);
  (void)DebugLog_Printf("[GPIOE] MODER=0x%08lX AFRL=0x%08lX PUPDR=0x%08lX OSPEEDR=0x%08lX\r\n",
                       (unsigned long)GPIOE->MODER, (unsigned long)GPIOE->AFR[0],
                       (unsigned long)GPIOE->PUPDR, (unsigned long)GPIOE->OSPEEDR);
  BoardSDRAM_Status sdram_status = BoardSDRAM_Initialize(&hsdram1, &sdram_report);
  if (sdram_status == BOARD_SDRAM_OK)
  {
    sdram_status = BoardSDRAM_TestMemory((volatile uint16_t *)BOARD_SDRAM_BASE_ADDRESS,
                                        BOARD_SDRAM_SIZE_BYTES, &sdram_report);
  }
  if (sdram_status != BOARD_SDRAM_OK)
  {
    (void)DebugLog_Printf("[FAIL] SDRAM status=%u phase=%s HAL=%u\r\n",
                         (unsigned)sdram_status, sdram_report.phase,
                         (unsigned)sdram_report.hal_status);
    if (sdram_status == BOARD_SDRAM_MEMORY_MISMATCH)
    {
      (void)DebugLog_Printf("[FAIL] addr=0x%08lX expected=0x%04X actual=0x%04X\r\n",
                           (unsigned long)sdram_report.failed_address,
                           (unsigned)sdram_report.expected, (unsigned)sdram_report.actual);
      BoardSDRAM_DiagnoseByteAccess(&hsdram1,
                                    (volatile uint16_t *)BOARD_SDRAM_BASE_ADDRESS,
                                    BOARD_SDRAM_SIZE_BYTES, &sdram_report);
    }
    Error_Handler();
  }
  (void)DebugLog_Printf("[PASS] SDRAM %lu bytes tested\r\n",
                       (unsigned long)sdram_report.tested_bytes);
  DebugLog_SetStage("remaining-peripheral-init");
  /* USER CODE END FMC_Init 2 */
}

static void MX_GPIO_Init(void)
{
  GPIO_InitTypeDef GPIO_InitStruct = {0};

  /* GPIO Ports Clock Enable */
  __HAL_RCC_GPIOE_CLK_ENABLE();
  __HAL_RCC_GPIOC_CLK_ENABLE();
  __HAL_RCC_GPIOI_CLK_ENABLE();
  __HAL_RCC_GPIOF_CLK_ENABLE();
  __HAL_RCC_GPIOH_CLK_ENABLE();
  __HAL_RCC_GPIOA_CLK_ENABLE();
  __HAL_RCC_GPIOB_CLK_ENABLE();
  __HAL_RCC_GPIOG_CLK_ENABLE();
  __HAL_RCC_GPIOD_CLK_ENABLE();

  /*Configure GPIO pin Output Level */
  HAL_GPIO_WritePin(GPIOC, H863_EN_Pin|LoRa_M0_Pin|LoRa_M1_Pin|Valve_EN_Pin
                          |Water_pump_E_Pin, GPIO_PIN_RESET);

  /*Configure GPIO pin Output Level */
  HAL_GPIO_WritePin(SPI_SDC_GPIO_Port, SPI_SDC_Pin, GPIO_PIN_SET);

  /*Configure GPIO pin Output Level */
  HAL_GPIO_WritePin(GPIOA, SPI_CLK_Pin|SPI_MOSI_Pin|LCD_SHUT_Pin, GPIO_PIN_RESET);

  /*Configure GPIO pin Output Level */
  HAL_GPIO_WritePin(GPIOB, SPI2_CS_Pin|FLOW_EN_Pin, GPIO_PIN_SET);

  /*Configure GPIO pin Output Level */
  HAL_GPIO_WritePin(GPIOD, PMU_EN1_Pin|PMU_EN2_Pin|PMU_EN4_Pin|BEEP_Pin
                          |LCD_RST_Pin|SSD2828_LCD_RESET_Pin, GPIO_PIN_RESET);

  /*Configure GPIO pin Output Level */
  HAL_GPIO_WritePin(SPI_NSS_GPIO_Port, SPI_NSS_Pin, GPIO_PIN_SET);

  /*Configure GPIO pin Output Level */
  HAL_GPIO_WritePin(PMU_EN3_GPIO_Port, PMU_EN3_Pin, GPIO_PIN_RESET);

  /*Configure GPIO pins : DN_KEY_Pin OK_KEY_Pin */
  GPIO_InitStruct.Pin = DN_KEY_Pin|OK_KEY_Pin;
  GPIO_InitStruct.Mode = GPIO_MODE_INPUT;
  GPIO_InitStruct.Pull = GPIO_PULLUP;
  HAL_GPIO_Init(GPIOE, &GPIO_InitStruct);

  /*Configure GPIO pin : Radar_OUT_Pin */
  GPIO_InitStruct.Pin = Radar_OUT_Pin;
  GPIO_InitStruct.Mode = GPIO_MODE_INPUT;
  GPIO_InitStruct.Pull = GPIO_NOPULL;
  HAL_GPIO_Init(Radar_OUT_GPIO_Port, &GPIO_InitStruct);

  /*Configure GPIO pins : H863_EN_Pin LoRa_M0_Pin LoRa_M1_Pin Valve_EN_Pin
                           Water_pump_E_Pin SPI_NSS_Pin */
  GPIO_InitStruct.Pin = H863_EN_Pin|LoRa_M0_Pin|LoRa_M1_Pin|Valve_EN_Pin
                          |Water_pump_E_Pin|SPI_NSS_Pin;
  GPIO_InitStruct.Mode = GPIO_MODE_OUTPUT_PP;
  GPIO_InitStruct.Pull = GPIO_NOPULL;
  GPIO_InitStruct.Speed = GPIO_SPEED_FREQ_LOW;
  HAL_GPIO_Init(GPIOC, &GPIO_InitStruct);

  /*Configure GPIO pins : SPI_SDC_Pin SPI_CLK_Pin SPI_MOSI_Pin LCD_SHUT_Pin */
  GPIO_InitStruct.Pin = SPI_SDC_Pin|SPI_CLK_Pin|SPI_MOSI_Pin|LCD_SHUT_Pin;
  GPIO_InitStruct.Mode = GPIO_MODE_OUTPUT_PP;
  GPIO_InitStruct.Pull = GPIO_NOPULL;
  GPIO_InitStruct.Speed = GPIO_SPEED_FREQ_LOW;
  HAL_GPIO_Init(GPIOA, &GPIO_InitStruct);

  /*Configure GPIO pin : SPI_MISO_Pin */
  GPIO_InitStruct.Pin = SPI_MISO_Pin;
  GPIO_InitStruct.Mode = GPIO_MODE_INPUT;
  GPIO_InitStruct.Pull = GPIO_NOPULL;
  HAL_GPIO_Init(SPI_MISO_GPIO_Port, &GPIO_InitStruct);

  /*Configure GPIO pin : FLOW_IN_Pin */
  GPIO_InitStruct.Pin = FLOW_IN_Pin;
  GPIO_InitStruct.Mode = GPIO_MODE_INPUT;
  GPIO_InitStruct.Pull = GPIO_NOPULL;
  HAL_GPIO_Init(FLOW_IN_GPIO_Port, &GPIO_InitStruct);

  /*Configure GPIO pins : SPI2_CS_Pin FLOW_EN_Pin */
  GPIO_InitStruct.Pin = SPI2_CS_Pin|FLOW_EN_Pin;
  GPIO_InitStruct.Mode = GPIO_MODE_OUTPUT_PP;
  GPIO_InitStruct.Pull = GPIO_NOPULL;
  GPIO_InitStruct.Speed = GPIO_SPEED_FREQ_LOW;
  HAL_GPIO_Init(GPIOB, &GPIO_InitStruct);

  /*Configure GPIO pins : PMU_EN1_Pin PMU_EN2_Pin PMU_EN4_Pin BEEP_Pin
                           LCD_RST_Pin SSD2828_LCD_RESET_Pin */
  GPIO_InitStruct.Pin = PMU_EN1_Pin|PMU_EN2_Pin|PMU_EN4_Pin|BEEP_Pin
                          |LCD_RST_Pin|SSD2828_LCD_RESET_Pin;
  GPIO_InitStruct.Mode = GPIO_MODE_OUTPUT_PP;
  GPIO_InitStruct.Pull = GPIO_NOPULL;
  GPIO_InitStruct.Speed = GPIO_SPEED_FREQ_LOW;
  HAL_GPIO_Init(GPIOD, &GPIO_InitStruct);

  /*Configure GPIO pin : PMU_EN3_Pin */
  GPIO_InitStruct.Pin = PMU_EN3_Pin;
  GPIO_InitStruct.Mode = GPIO_MODE_OUTPUT_PP;
  GPIO_InitStruct.Pull = GPIO_NOPULL;
  GPIO_InitStruct.Speed = GPIO_SPEED_FREQ_LOW;
  HAL_GPIO_Init(PMU_EN3_GPIO_Port, &GPIO_InitStruct);

  /*Configure GPIO pin : LCDBL_EN_Pin */
  GPIO_InitStruct.Pin = LCDBL_EN_Pin;
  GPIO_InitStruct.Mode = GPIO_MODE_INPUT;
  GPIO_InitStruct.Pull = GPIO_NOPULL;
  HAL_GPIO_Init(LCDBL_EN_GPIO_Port, &GPIO_InitStruct);

  /*Configure GPIO pins : ON_OFF_KEY_Pin SET_KEY_Pin UP_KEY_Pin */
  GPIO_InitStruct.Pin = ON_OFF_KEY_Pin|SET_KEY_Pin|UP_KEY_Pin;
  GPIO_InitStruct.Mode = GPIO_MODE_INPUT;
  GPIO_InitStruct.Pull = GPIO_PULLUP;
  HAL_GPIO_Init(GPIOG, &GPIO_InitStruct);

  /* USER CODE BEGIN MX_GPIO_Init_2 */
  /* Keep RESET low while overriding generated push-pull mode. A released
     open drain requires an external pull-up to the panel's switched 1V8. */
  HAL_GPIO_WritePin(LCD_RST_GPIO_Port, LCD_RST_Pin, GPIO_PIN_RESET);
  GPIO_InitStruct.Pin = LCD_RST_Pin;
  GPIO_InitStruct.Mode = GPIO_MODE_OUTPUT_OD;
  GPIO_InitStruct.Pull = GPIO_NOPULL;
  GPIO_InitStruct.Speed = GPIO_SPEED_FREQ_LOW;
  HAL_GPIO_Init(LCD_RST_GPIO_Port, &GPIO_InitStruct);
  /* USER CODE END MX_GPIO_Init_2 */
}

void Error_Handler(void)
{
  /* USER CODE BEGIN Error_Handler_Debug */
  /* User can add his own implementation to report the HAL error return state */
  (void)DebugLog_Printf("[FATAL] stage=%s; startup stopped.\r\n", DebugLog_GetStage());
  __disable_irq();
  while (1)
  {
  }
  /* USER CODE END Error_Handler_Debug */
}
